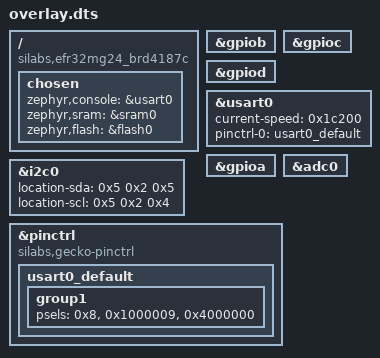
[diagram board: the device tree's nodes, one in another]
/ {
	compatible = "silabs,efr32mg24_brd4187c", "silabs,efr32mg24";
	chosen {
		zephyr,console = &usart0;
		zephyr,sram = &sram0;
		zephyr,flash = &flash0;
	};
};
&gpiob{
	status = "okay";
};
&gpioc{
	status = "okay";
};
&gpiod{
	status = "okay";
};
&usart0{
	status = "okay";
	current-speed = < 0x1c200 >;
	pinctrl-0 = < &usart0_default >;
	pinctrl-names = "default";
};
&gpioa{
	status = "okay";
};
&i2c0{
	status = "okay";
	location-sda = < 0x5 0x2 0x5 >;
	location-scl = < 0x5 0x2 0x4 >;
};
&adc0{
	status = "okay";
};
&pinctrl{
	compatible = "silabs,gecko-pinctrl";
	usart0_default: usart0_default {
		group1 {
			psels = < 0x8 >, < 0x1000009 >, < 0x4000000 >;
		};
	};
};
